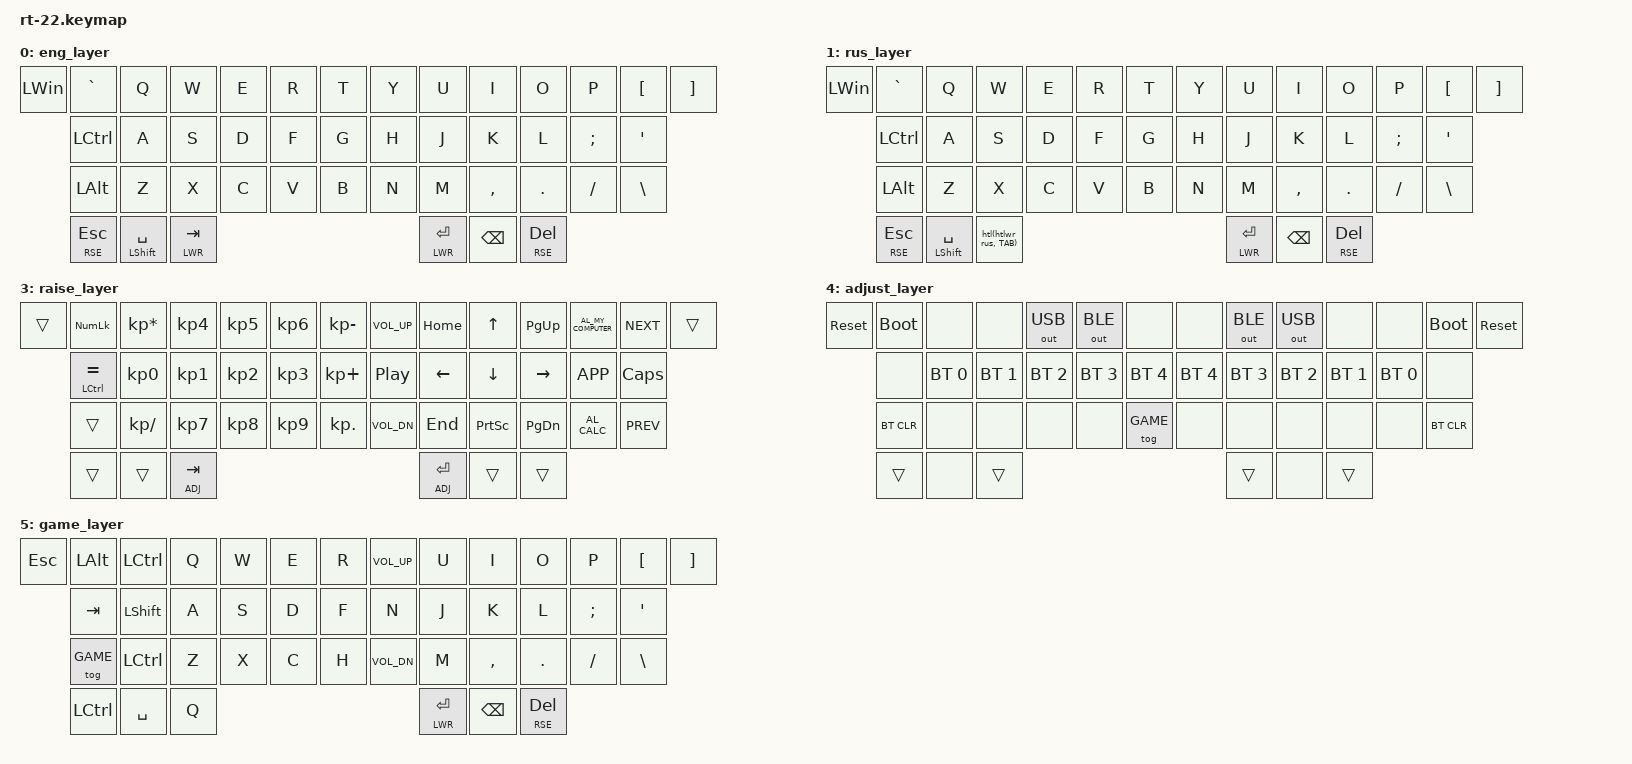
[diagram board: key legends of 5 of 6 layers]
/*
 * Copyright (c) 2021 The ZMK Contributors
 *
 * SPDX-License-Identifier: MIT
 */

#include <behaviors.dtsi>
#include <dt-bindings/zmk/keys.h>
#include <dt-bindings/zmk/bt.h>
#include <dt-bindings/zmk/outputs.h>

#define ENG 0
#define RUS 1
#define LWR 2
#define RSE 3
#define ADJ 4
#define GAME 5

#define SWITCH_COMBO_TAP_MS 30
#define SWITCH_COMBO_WAIT_MS 0
#define HOLD_SWITHC_TAPPING_MS 150
#define HOLD_SWITHC_QUICK_TAP_MS 150
#define COMBO_TIMEOUT 200


/* Macro macro: */
// source of macro https://github.com/AlaaSaadAbdo/zmk-config/blob/master/config/macros.dtsi
#define str(s) #s
#define MACRO(NAME, BINDINGS, WAITMS, TAPMS) \
  macro_##NAME: macro_##NAME { \
      compatible = "zmk,behavior-macro"; \
      label = str(macro_##NAME); \
      #binding-cells = <0>; \
      wait-ms = <WAITMS>; \
      tap-ms = <TAPMS>; \
      bindings = <BINDINGS>; \
  };
// sample macro: MACRO(nav, &macro_tap &kp LC(LS(N2)) &mo LWR &macro_pause_for_release &macro_release &mo LWR, 0, 10)

// Combination for lang switching set in system
#define langswitch(num) LS(LC(num))
// Switch lang, than hold mo layer
#define LANG_MACRO(NAME, LAYER, NUM, RETURN_NUM) \
  macro_##NAME: macro_##NAME { \
      compatible = "zmk,behavior-macro"; \
      label = str(macro_##NAME); \
      #binding-cells = <0>; \
      wait-ms = <SWITCH_COMBO_WAIT_MS>; \
      tap-ms = <SWITCH_COMBO_TAP_MS>; \
      bindings \
        = <&macro_tap &kp langswitch(NUM)> \
        , <&macro_press &mo LAYER> \
        , <&macro_pause_for_release> \
        , <&macro_tap_time SWITCH_COMBO_TAP_MS> \
        , <&macro_tap &kp langswitch(RETURN_NUM)> \
        , <&macro_release &mo LAYER> \ 
        ; \
  };

// Switch lang, than press key
#define KP_LANG_MACRO(NAME, KEY, NUM, RETURN_NUM) \
  kp_##NAME: macro_##NAME { \
      compatible = "zmk,behavior-macro"; \
      label = str(macro_##NAME); \
      #binding-cells = <0>; \
      wait-ms = <SWITCH_COMBO_WAIT_MS>; \
      tap-ms = <SWITCH_COMBO_TAP_MS>; \
      bindings \
        = <&macro_tap &kp langswitch(NUM)> \
        , <&macro_tap &kp KEY> \
        , <&macro_tap_time SWITCH_COMBO_TAP_MS> \
        , <&macro_tap &kp langswitch(RETURN_NUM)> \
        ; \
  };

// Switch lang, then set to layer
#define TO_MACRO(NAME, LAYER, NUM) \
  tom_##NAME: tom_##NAME { \
      compatible = "zmk,behavior-macro"; \
      label = str(tom_##NAME); \
      #binding-cells = <0>; \
      wait-ms = <SWITCH_COMBO_WAIT_MS>; \
      tap-ms = <SWITCH_COMBO_TAP_MS>; \
      bindings \
        = <&macro_tap &kp langswitch(NUM)> \
        , <&macro_tap &to LAYER> \
        ; \
  };
// Shortcut for call hold tap with macro
#define htl(flavor, key) &flavor 0 key

// Macro on hold, kp on tap
#define HOLD_COMBO_BEHAVIOR(NAME, MACRO) \
  ht##NAME: hold_tap_##NAME { \
        compatible = "zmk,behavior-hold-tap"; \
        label = str(HOLD_TAP_##NAME); \
        #binding-cells = <2>; \
        flavor = "tap-preferred"; \
        tapping-term-ms = <HOLD_SWITHC_TAPPING_MS>; \
        bindings = ##MACRO, <&kp>; \
        quick_tap_ms = <HOLD_SWITHC_QUICK_TAP_MS>; \
    };

/* macro: */

&lt { quick_tap_ms = <200>; };
&mt { quick_tap_ms = <200>; };


/ { 
        behaviors {
                rulang: russian_language {
                compatible = "zmk,behavior-mod-morph";
                label = "RUS_LANG";
                #binding-cells = <0>;
                bindings = <&kp LALT>, <&kp LC(N1)>;
                mods = <(LSHIFT|RSHIFT)>;
                keep-mods = <(LSHIFT|RSHIFT)>;
                };
                HOLD_COMBO_BEHAVIOR(lwr_rus, <&macro_lwr_rus>)
        };
        macros {
                LANG_MACRO(lwr_rus, LWR, N2, N1)
                TO_MACRO(rus, RUS, N1)
                TO_MACRO(eng, ENG, N2)
                KP_LANG_MACRO(number, HASH, N1, N2)
        };
        combos {
                compatible = "zmk,combos";
                combo_eng_rus {
                        timeout-ms = <COMBO_TIMEOUT>;
                        key-positions = <26 39>;
                        layers = <ENG>, <RUS>;
                        bindings = <&tom_rus>;
                    };
                combo_rus_eng {
                        timeout-ms = <COMBO_TIMEOUT>;
                        // key-positions = <31 39>; // left half test positions
                        key-positions = <37 42>; // right half
                        layers = <ENG>, <RUS>;
                        bindings = <&tom_eng>;
                    };
                combo_number_on_lower {
                        timeout-ms = <COMBO_TIMEOUT>;
                        // key-positions = <31 39>; // left half test positions
                        key-positions = <0>; // right half
                        layers = <LWR>;
                        bindings = <&kp_number>;
                    };
        };
        keymap {
                compatible = "zmk,keymap";

                eng_layer {
// -----------------------------------------------------------------------------------------
// |  GUI |   ~  |  Q  |  W  |  E  |  R  |  T  |   |  Y  |  U   |  I  |  O  |  P  |  [   |  ]  |
//        | CTRL |  A  |  S  |  D  |  F  |  G  |   |  H  |  J   |  K  |  L  |  ;  |  '   |
//        | LALT |  Z  |  X  |  C  |  V  |  B  |   |  N  |  M   |  ,  |  .  |  /  | \ |
//                    | ESC | SPC | TAB |   | ENT | BSPC | DEL |
                        bindings = <
   &kp LWIN &kp GRAVE &kp Q &kp W &kp E &kp R &kp T         &kp Y &kp U  &kp I     &kp O   &kp P    &kp LBKT  &kp RBKT
            &kp LCTRL &kp A &kp S &kp D &kp F &kp G         &kp H &kp J  &kp K     &kp L   &kp SEMI &kp SQT
            &kp LALT   &kp Z &kp X &kp C &kp V &kp B         &kp N &kp M  &kp COMMA &kp DOT &kp FSLH &kp BSLH
            &lt RSE ESC &mt LSHFT SPACE &lt LWR TAB         &lt LWR RET &kp BSPC &lt RSE DEL
                        >;
                };
                rus_layer {
// -----------------------------------------------------------------------------------------
// |  GUI |   ~  |  Q  |  W  |  E  |  R  |  T  |   |  Y  |  U   |  I  |  O  |  P  |  [   |  ]  |
//        | CTRL |  A  |  S  |  D  |  F  |  G  |   |  H  |  J   |  K  |  L  |  ;  |  '   |
//        | LALT |  Z  |  X  |  C  |  V  |  B  |   |  N  |  M   |  ,  |  .  |  /  | \ |
//                    | ESC | SPC | TAB |   | ENT | BSPC | DEL |
                        bindings = <
        &kp LWIN &kp GRAVE &kp Q &kp W &kp E &kp R &kp T         &kp Y &kp U  &kp I     &kp O   &kp P    &kp LBKT  &kp RBKT
                &kp LCTRL &kp A &kp S &kp D &kp F &kp G        &kp H &kp J  &kp K     &kp L   &kp SEMI &kp SQT
                &kp LALT   &kp Z &kp X &kp C &kp V &kp B         &kp N &kp M  &kp COMMA &kp DOT &kp FSLH &kp BSLH
                &lt RSE ESC &mt LSHFT SPACE htl(htlwr_rus, TAB)         &lt LWR RET &kp BSPC &lt RSE DEL
                        >;
                };
                lower_layer {
// -----------------------------------------------------------------------------------------
// |     |  _  |  F1 |  F2 |  F3 |  F4 |  F5 |   |  F6 |  F7 |  F8 |  F9 | F10  | F11 | F12 |
//       |  =  |  !  |  @  |  #  |  $  |  %  |   |  ^  |  &  |  *  |  (  |  )   |  -  |
//       |  +  |     |     |     |     |  RD |   |  RD |SHIFT|     |     |SCREEN|     |
//                   | GUI |     | SPC |         | ENT |     | ALT |
                       bindings = <
   &none &kp UNDER       &kp F1    &kp F2    &kp F3      &kp F4    &kp F5               &kp F6        &kp F7    &kp F8   &kp F9   &kp F10       &kp F11   &mt RGUI F12
          &mt LCTRL HASH &kp LPAR  &kp EQUAL    &kp EXCL    &kp MINUS  &kp LS(BSLH)            &kp AMPS     &kp LS(FSLH)  &kp LS(SQT) &kp LS(SEMI) &kp RPAR  &kp DLLR
          &mt LALT PLUS   &kp LC(Z) &kp LC(X) &kp LC(C)   &kp AT &kp LC(LS(LA(B)))    &kp LC(LS(B)) &kp PRCNT &trans    &kp LSHFT   &kp LG(LS(S)) &kp CARET
                                              &lt ADJ ESC &trans    &trans               &trans        &trans    &lt ADJ DEL
                       >;
                };
                raise_layer {
// -----------------------------------------------------------------------------------------
// |     | NMLK |  *  |  4  |  5  |  6  |  -  |   | VOLU| HOME| UP  | PGUP |MYCOMP| NEXT |     |
//       |   =  |  0  |  1  |  2  |  3  |  +  |   |PAUSE| LEFT| DOWN| RGHT | APP  | CAPS |
//       |      |  /  |  7  |  8  |  9  |  .  |   | VOLD| END | PRSC| PGDN | CALC | PREV |
//                          |     |     | ADJ |   | ADJ |     |     |
                        bindings = <       
   &trans &kp KP_NUM      &kp KP_MULTIPLY &kp KP_N4 &kp KP_N5 &kp KP_N6 &kp KP_MINUS        &kp C_VOL_UP &kp HOME &kp UP    &kp PG_UP &kp C_AL_MY_COMPUTER &kp C_NEXT &trans
          &mt LCTRL EQUAL &kp KP_N0       &kp KP_N1 &kp KP_N2 &kp KP_N3 &kp KP_PLUS         &kp C_PP     &kp LEFT &kp DOWN  &kp RIGHT &kp K_APP            &kp CAPS
          &trans          &kp KP_SLASH    &kp KP_N7 &kp KP_N8 &kp KP_N9 &kp KP_DOT          &kp C_VOL_DN &kp END  &kp PSCRN &kp PG_DN &kp C_AL_CALC        &kp C_PREV
                                                    &trans    &trans    &lt ADJ TAB         &lt ADJ RET  &trans   &trans
                        >;
                };
                adjust_layer {
// -----------------------------------------------------------------------------------------
// | RST | BLDR |     |     | USB | BLE |     |   |     | BLE | USB |     |     | BLDR | RST |
//       |      | BT0 | BT1 | BT2 | BT3 | BT4 |   | BT4 | BT3 | BT2 | BT1 | BT0 |      |
//       | BTCLR|     |     |     |     |     |   |     |     |     |     |     | BTCLR|
//                          |     |     |     |   |     |     |     |
                        bindings = <              
   &sys_reset &bootloader  &none        &none        &out OUT_USB &out OUT_BLE &none           &none        &out OUT_BLE &out OUT_USB &none        &none         &bootloader &sys_reset
          &none        &bt BT_SEL 0 &bt BT_SEL 1 &bt BT_SEL 2 &bt BT_SEL 3 &bt BT_SEL 4    &bt BT_SEL 4 &bt BT_SEL 3 &bt BT_SEL 2 &bt BT_SEL 1 &bt BT_SEL 0  &none
          &bt BT_CLR   &none        &none        &none        &none        &tog GAME       &none        &none        &none        &none        &none         &bt BT_CLR
                                                 &trans       &none        &trans          &trans       &none        &trans
                        >;
                };
                game_layer {
// -----------------------------------------------------------------------------------------
// |  GUI |   ~  |  Q  |  W  |  E  |  R  |  T  |   |  Y  |  U   |  I  |  O  |  P  |  [   |  ]  |
//        | CTRL |  A  |  S  |  D  |  F  |  G  |   |  H  |  J   |  K  |  L  |  ;  |  '   |
//        | LALT |  Z  |  X  |  C  |  V  |  B  |   |  N  |  M   |  ,  |  .  |  /  | \ |
//                    | ESC | SPC | TAB |   | ENT | BSPC | DEL |
                        bindings = <
   &kp ESC  &kp LALT  &kp LCTRL &kp Q &kp W &kp E &kp R         &kp C_VOL_UP &kp U  &kp I     &kp O   &kp P    &kp LBKT  &kp RBKT
            &kp TAB   &kp LSHFT &kp A &kp S &kp D &kp F         &kp N &kp J  &kp K     &kp L   &kp SEMI &kp SQT
            &tog GAME &kp LCTRL &kp Z &kp X &kp C &kp H         &kp C_VOL_DN &kp M  &kp COMMA &kp DOT &kp FSLH &kp BSLH
                              &kp LCTRL &kp SPACE &kp Q         &lt LWR RET &kp BSPC &lt RSE DEL
                        >;
                };
        };
};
